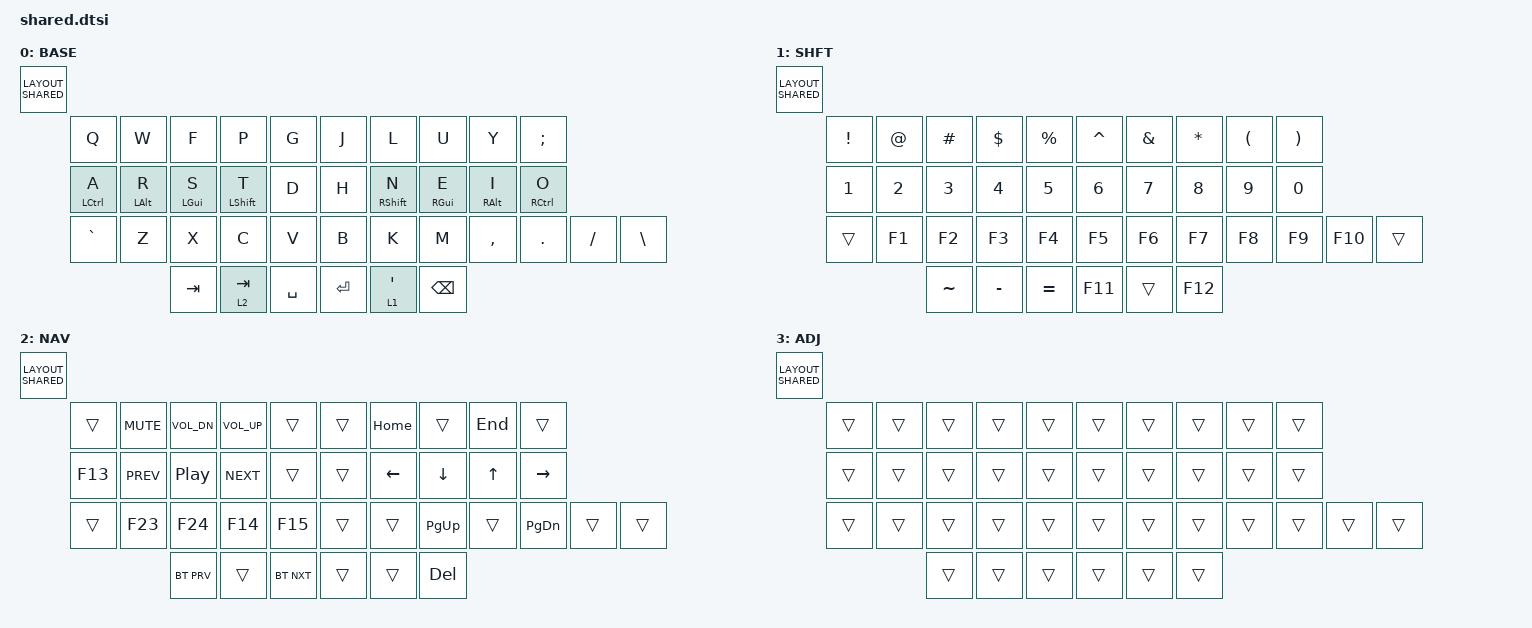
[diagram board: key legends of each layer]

#include <behaviors.dtsi>
#include <dt-bindings/zmk/bt.h>
#include <dt-bindings/zmk/keys.h>

#define BASE 0
#define NAV  1
#define SYM  2
#define ADJ  3

/ {
    behaviors {
        gresc: grave_escape {
            compatible = "zmk,behavior-mod-morph";
            #binding-cells = <0>;
            bindings = <&kp ESC>, <&kp GRAVE>;
            mods = <(MOD_LGUI|MOD_LSFT|MOD_RGUI|MOD_RSFT)>;
        };

        hml: home_row_mod_left {
            compatible = "zmk,behavior-hold-tap";
            #binding-cells = <2>;
            flavor = "balanced";
            require-prior-idle-ms = <150>;
            tapping-term-ms = <280>;
            quick-tap-ms = <175>;
            bindings = <&kp>, <&kp>;
            hold-trigger-key-positions = <RIGHT_SIDE_KEYS>;
            hold-trigger-on-release;
        };

        hmr: home_row_mod_right {
            compatible = "zmk,behavior-hold-tap";
            #binding-cells = <2>;
            flavor = "balanced";
            require-prior-idle-ms = <150>;
            tapping-term-ms = <280>;
            quick-tap-ms = <175>;
            bindings = <&kp>, <&kp>;
            hold-trigger-key-positions = <LEFT_SIDE_KEYS>;
            hold-trigger-on-release;
        };
    };

    combos { compatible = "zmk,combos"; };

    keymap {
        compatible = "zmk,keymap";

        base_layer {
            display-name = "BASE";
            bindings = <LAYOUT_SHARED(
                &kp Q,         &kp W,            &kp F,        &kp P,         &kp G,    &kp J,    &kp L,          &kp U,        &kp Y,        &kp SEMI,
                &hml LCTRL A,  &hml LEFT_ALT R,  &hml LGUI S,  &hml LSHFT T,  &kp D,    &kp H,    &hmr RSHIFT N,  &hmr RGUI E,  &hmr RALT I,  &hmr RCTRL O,
                &kp GRAVE,     &kp Z,            &kp X,        &kp C,         &kp V,    &kp B,    &kp K,          &kp M,        &kp COMMA,    &kp DOT,      &kp SLASH,  &kp BSLH,
                                                 &kp TAB,      &lt 2 TAB,     &kp SPACE, &kp RET,  &lt 1 APOS,     &kp BSPC
            )>;
        };

        shift_layer {
            display-name = "SHFT";
            bindings = <LAYOUT_SHARED(
                &kp EXCL,  &kp AT,  &kp HASH,   &kp DLLR,   &kp PRCNT,    &kp CARET,  &kp AMPS,  &kp STAR,  &kp LPAR,  &kp RPAR,
                &kp N1,    &kp N2,  &kp N3,     &kp N4,     &kp N5,       &kp N6,     &kp N7,    &kp N8,    &kp N9,    &kp N0,
                &trans,    &kp F1,  &kp F2,     &kp F3,     &kp F4,       &kp F5,     &kp F6,    &kp F7,    &kp F8,    &kp F9,    &kp F10,  &trans,
                                    &kp TILDE,  &kp MINUS,  &kp EQUAL,    &kp F11,    &trans,    &kp F12
            )>;
        };

        nav_layer {
            display-name = "NAV";
            bindings = <LAYOUT_SHARED(
                &trans,   &kp C_MUTE,  &kp C_VOL_DN,      &kp C_VOL_UP,  &trans,        &trans,  &kp HOME,   &trans,    &kp END,    &trans,
                &kp F13,  &kp C_PREV,  &kp C_PLAY_PAUSE,  &kp C_NEXT,    &trans,        &trans,  &kp LEFT,   &kp DOWN,  &kp UP,     &kp RIGHT,
                &trans,   &kp F23,     &kp F24,           &kp F14,       &kp F15,       &trans,  &trans,  &kp PG_UP,  &trans,    &kp PG_DN,  &trans,  &trans,
                                       &bt BT_PRV,        &trans,        &bt BT_NXT,    &trans,  &trans,     &kp DEL
            )>;
        };

        adj_layer {
            display-name = "ADJ";
            bindings = <LAYOUT_SHARED(
                &trans,  &trans,  &trans,  &trans,  &trans,    &trans,  &trans,  &trans,  &trans,  &trans,
                &trans,  &trans,  &trans,  &trans,  &trans,    &trans,  &trans,  &trans,  &trans,  &trans,
                &trans,  &trans,  &trans,  &trans,  &trans,  &trans,    &trans,  &trans,  &trans,  &trans,  &trans,  &trans,
                                  &trans,  &trans,  &trans,    &trans,  &trans,  &trans
            )>;
        };
    };
};
